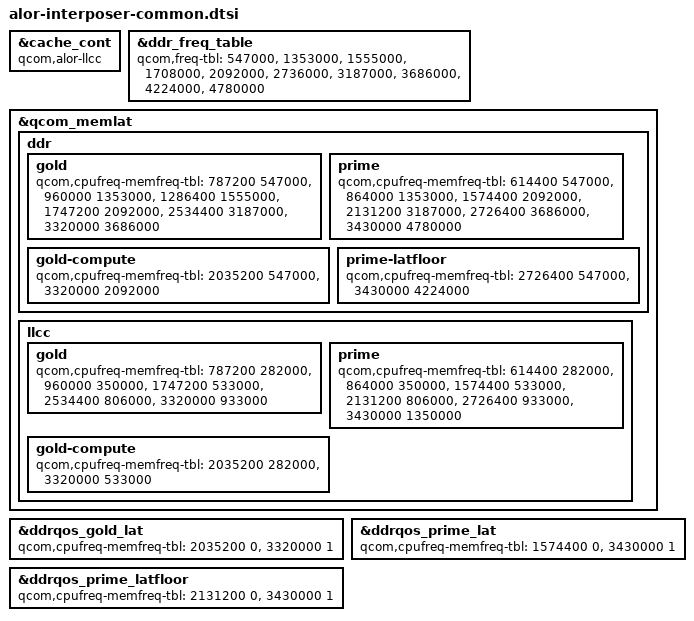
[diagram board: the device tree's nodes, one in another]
// SPDX-License-Identifier: BSD-3-Clause
/*
 * Copyright (c) 2025 Qualcomm Innovation Center, Inc. All rights reserved.
 */

&cache_cont {
		compatible = "qcom,alor-llcc";
};

/delete-node/ &spss_pas;
/delete-node/ &qcom_spcom;
/delete-node/ &spss_utils;
/delete-node/ &qcom_sp_hlos;
/delete-node/ &qcom_secure_sp_tz;
/delete-node/ &qcom_secure_sp_modem;
/delete-node/ &sp_mem;
/delete-node/ &spu_tz_shared_mem;
/delete-node/ &spu_modem_shared_mem;
/delete-node/ &spss_region_mem;

&ddr_freq_table {
	qcom,freq-tbl =
		<  547000 >,
		< 1353000 >,
		< 1555000 >,
		< 1708000 >,
		< 2092000 >,
		< 2736000 >,
		< 3187000 >,
		< 3686000 >,
		< 4224000 >,
		< 4780000 >;
};

&qcom_memlat {
	ddr {
		gold {
			qcom,cpufreq-memfreq-tbl =
				<  787200  547000 >,
				<  960000 1353000 >,
				< 1286400 1555000 >,
				< 1747200 2092000 >,
				< 2534400 3187000 >,
				< 3320000 3686000 >;
		};

		prime {
			qcom,cpufreq-memfreq-tbl =
				<  614400  547000 >,
				<  864000 1353000 >,
				< 1574400 2092000 >,
				< 2131200 3187000 >,
				< 2726400 3686000 >,
				< 3430000 4780000 >;
		};

		gold-compute {
			qcom,cpufreq-memfreq-tbl =
				< 2035200  547000 >,
				< 3320000 2092000 >;
		};

		prime-latfloor {
			qcom,cpufreq-memfreq-tbl =
				< 2726400  547000 >,
				< 3430000 4224000 >;
		};
	};

	llcc {
		gold {
			qcom,cpufreq-memfreq-tbl =
				<  787200  282000 >,
				<  960000  350000 >,
				< 1747200  533000 >,
				< 2534400  806000 >,
				< 3320000  933000 >;
		};

		prime {
			qcom,cpufreq-memfreq-tbl =
				<  614400  282000 >,
				<  864000  350000 >,
				< 1574400  533000 >,
				< 2131200  806000 >,
				< 2726400  933000 >,
				< 3430000 1350000 >;
		};

		gold-compute {
			qcom,cpufreq-memfreq-tbl =
				< 2035200  282000 >,
				< 3320000  533000 >;
		};
	};
};

&ddrqos_gold_lat {
	qcom,cpufreq-memfreq-tbl =
		< 2035200 0 >,
		< 3320000 1 >;
};

&ddrqos_prime_lat {
	qcom,cpufreq-memfreq-tbl =
		< 1574400 0 >,
		< 3430000 1 >;
};

&ddrqos_prime_latfloor {
	qcom,cpufreq-memfreq-tbl =
		< 2131200 0 >,
		< 3430000 1 >;
};
